# VIP1_VPDMA register map
Vendor: Texas Instruments
Registers are 32-bit, access per field, reset 0x0 unless marked. A register's access mark holds for its fields unless they carry their own. Offsets are as the file gives them; [hi:lo] are bit positions; {n}, {i} and the like mark numbered series; 'fields as' and 'values as' point back to an identical list.

## VIP1_VPDMA (part 5 of 5)
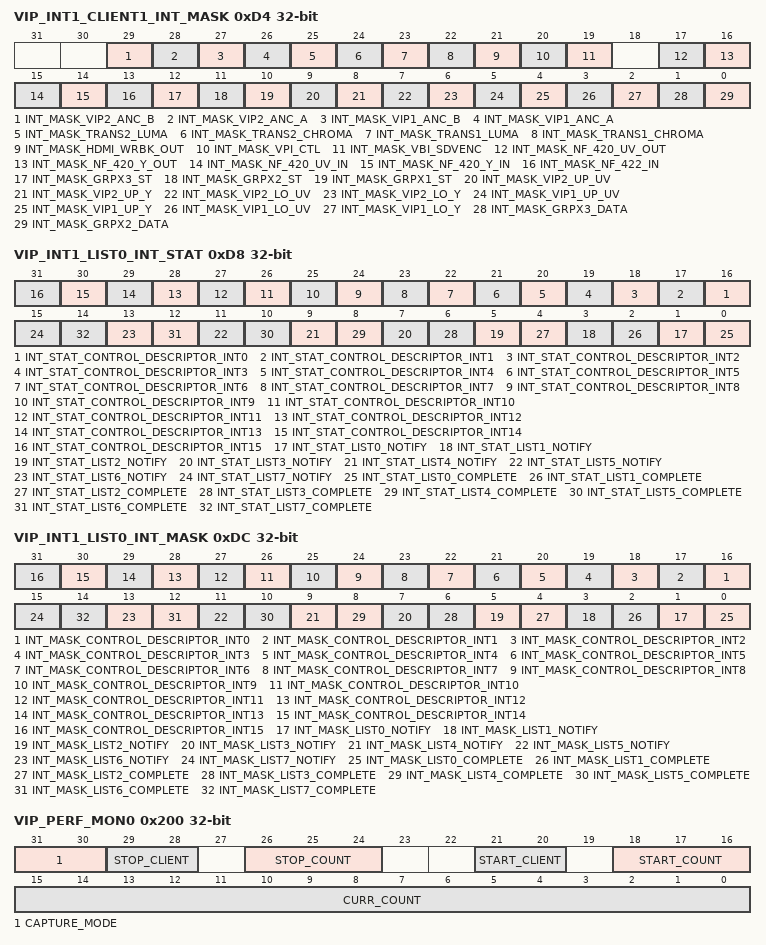
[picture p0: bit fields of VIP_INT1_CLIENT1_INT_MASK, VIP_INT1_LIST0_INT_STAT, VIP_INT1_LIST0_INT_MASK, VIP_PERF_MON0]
0xD4 VIP_INT1_CLIENT1_INT_MASK — The register gives the information of the interrupts that should be masked and not generate an interrupt for vpdma_int1.
  [29] INT_MASK_VIP2_ANC_B rw — The interrupt for should generate an interrupt on interrupt vpdma_int1. Write a 1 for the interrupt event to trigger the interrupt signal.
  [28] INT_MASK_VIP2_ANC_A rw — The interrupt for should generate an interrupt on interrupt vpdma_int1. Write a 1 for the interrupt event to trigger the interrupt signal.
  [27] INT_MASK_VIP1_ANC_B rw — The interrupt for should generate an interrupt on interrupt vpdma_int1. Write a 1 for the interrupt event to trigger the interrupt signal.
  [26] INT_MASK_VIP1_ANC_A rw — The interrupt for should generate an interrupt on interrupt vpdma_int1. Write a 1 for the interrupt event to trigger the interrupt signal.
  [25] INT_MASK_TRANS2_LUMA rw — The interrupt for should generate an interrupt on interrupt vpdma_int1. Write a 1 for the interrupt event to trigger the interrupt signal.
  [24] INT_MASK_TRANS2_CHROMA rw — The interrupt for should generate an interrupt on interrupt vpdma_int1. Write a 1 for the interrupt event to trigger the interrupt signal.
  [23] INT_MASK_TRANS1_LUMA rw — The interrupt for should generate an interrupt on interrupt vpdma_int1. Write a 1 for the interrupt event to trigger the interrupt signal.
  [22] INT_MASK_TRANS1_CHROMA rw — The interrupt for should generate an interrupt on interrupt vpdma_int1. Write a 1 for the interrupt event to trigger the interrupt signal.
  [21] INT_MASK_HDMI_WRBK_OUT rw — The interrupt for should generate an interrupt on interrupt vpdma_int1. Write a 1 for the interrupt event to trigger the interrupt signal.
  [20] INT_MASK_VPI_CTL rw — The interrupt for should generate an interrupt on interrupt vpdma_int1. Write a 1 for the interrupt event to trigger the interrupt signal.
  [19] INT_MASK_VBI_SDVENC rw — The interrupt for should generate an interrupt on interrupt vpdma_int1. Write a 1 for the interrupt event to trigger the interrupt signal.
  [17] INT_MASK_NF_420_UV_OUT rw — The interrupt for should generate an interrupt on interrupt vpdma_int1. Write a 1 for the interrupt event to trigger the interrupt signal.
  [16] INT_MASK_NF_420_Y_OUT rw — The interrupt for should generate an interrupt on interrupt vpdma_int1. Write a 1 for the interrupt event to trigger the interrupt signal.
  [15] INT_MASK_NF_420_UV_IN rw — The interrupt for should generate an interrupt on interrupt vpdma_int1. Write a 1 for the interrupt event to trigger the interrupt signal.
  [14] INT_MASK_NF_420_Y_IN rw — The interrupt for should generate an interrupt on interrupt vpdma_int1. Write a 1 for the interrupt event to trigger the interrupt signal.
  [13] INT_MASK_NF_422_IN rw — The interrupt for should generate an interrupt on interrupt vpdma_int1. Write a 1 for the interrupt event to trigger the interrupt signal.
  [12] INT_MASK_GRPX3_ST rw — The interrupt for should generate an interrupt on interrupt vpdma_int1. Write a 1 for the interrupt event to trigger the interrupt signal.
  [11] INT_MASK_GRPX2_ST rw — The interrupt for should generate an interrupt on interrupt vpdma_int1. Write a 1 for the interrupt event to trigger the interrupt signal.
  [10] INT_MASK_GRPX1_ST rw — The interrupt for should generate an interrupt on interrupt vpdma_int1. Write a 1 for the interrupt event to trigger the interrupt signal.
  [9] INT_MASK_VIP2_UP_UV rw — The interrupt for should generate an interrupt on interrupt vpdma_int1. Write a 1 for the interrupt event to trigger the interrupt signal.
  [8] INT_MASK_VIP2_UP_Y rw — The interrupt for should generate an interrupt on interrupt vpdma_int1. Write a 1 for the interrupt event to trigger the interrupt signal.
  [7] INT_MASK_VIP2_LO_UV rw — The interrupt for should generate an interrupt on interrupt vpdma_int1. Write a 1 for the interrupt event to trigger the interrupt signal.
  [6] INT_MASK_VIP2_LO_Y rw — The interrupt for should generate an interrupt on interrupt vpdma_int1. Write a 1 for the interrupt event to trigger the interrupt signal.
  [5] INT_MASK_VIP1_UP_UV rw — The interrupt for should generate an interrupt on interrupt vpdma_int1. Write a 1 for the interrupt event to trigger the interrupt signal.
  [4] INT_MASK_VIP1_UP_Y rw — The interrupt for should generate an interrupt on interrupt vpdma_int1. Write a 1 for the interrupt event to trigger the interrupt signal.
  [3] INT_MASK_VIP1_LO_UV rw — The interrupt for should generate an interrupt on interrupt vpdma_int1. Write a 1 for the interrupt event to trigger the interrupt signal.
  [2] INT_MASK_VIP1_LO_Y rw — The interrupt for should generate an interrupt on interrupt vpdma_int1. Write a 1 for the interrupt event to trigger the interrupt signal.
  [1] INT_MASK_GRPX3_DATA rw — The interrupt for should generate an interrupt on interrupt vpdma_int1. Write a 1 for the interrupt event to trigger the interrupt signal.
  [0] INT_MASK_GRPX2_DATA rw — The interrupt for should generate an interrupt on interrupt vpdma_int1. Write a 1 for the interrupt event to trigger the interrupt signal.
0xD8 VIP_INT1_LIST0_INT_STAT rw — This register gives the information of the interrupts that have triggered since last cleared by the process that is servicing vpdma_int1.
  [n+16] INT_STAT_CONTROL_DESCRIPTOR_INT{n} (n=0..15) — A Send Interrupt Control Descriptor has been received by the list manager with a source value of {n}. This event will cause a one to be set in this register until cleared by software. Write a 1 to this field to clear the value.
  [2n+1] INT_STAT_LIST{n}_NOTIFY (n=0..7) — A channel set by List {n} has completed and the Notify bit had been set in the descriptor for that channel. This event will cause a one to be set in this register until cleared by software. Write a 1 to this field to clear the value.
  [2n] INT_STAT_LIST{n}_COMPLETE (n=0..7) — List {n} has completed and a new list can be loaded. This event will cause a one to be set in this register until cleared by software. Write a 1 to this field to clear the value.
0xDC VIP_INT1_LIST0_INT_MASK rw — The register gives the information of the interrupts that should be masked and not generate an interrupt for vpdma_int1.
  [n+16] INT_MASK_CONTROL_DESCRIPTOR_INT{n} (n=0..15) — The interrupt for should generate an interrupt on interrupt vpdma_int1. Write a 1 for the interrupt event to trigger the interrupt signal.
  [2n+1] INT_MASK_LIST{n}_NOTIFY (n=0..7) — The interrupt for should generate an interrupt on interrupt vpdma_int1. Write a 1 for the interrupt event to trigger the interrupt signal.
  [2n] INT_MASK_LIST{n}_COMPLETE (n=0..7) — The interrupt for should generate an interrupt on interrupt vpdma_int1. Write a 1 for the interrupt event to trigger the interrupt signal.
0x200 VIP_PERF_MON0 — The register can be used to capture timing differences between events in the VPDMA\
  [31:30] CAPTURE_MODE rw — Sets how the counter should be updated. Updating this value will also clear the current counter stored value. 0: Running Average 1: Minimum Value 2: Maximum Value 3: Last Value
  [29:28] STOP_CLIENT rw — Sets the client whose event stops the performance monitor counter. 0: 1: vip2_anc_b 2: 3:
  [26:24] STOP_COUNT rw — Sets the value that stops the performance monitor counter. 0: command request 1: command accept 2: data request 3: data rcvd 4: data empty 5: data full 6: frame start 7: frame end
  [21:20] START_CLIENT rw — Sets the client whose event starts the performance monitor counter. 0: 1: vip2_anc_b 2: 3:
  [18:16] START_COUNT rw — Sets the value that starts the performance monitor counter. 0: command request 1: command accept 2: data request 3: data rcvd 4: data empty 5: data full 6: frame start 7: frame end
  [15:0] CURR_COUNT ro — The current value of the perfomance monitor counter
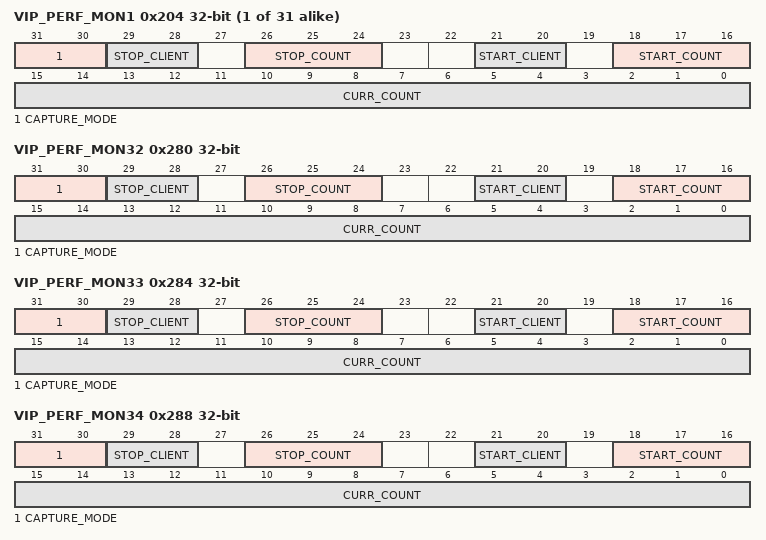
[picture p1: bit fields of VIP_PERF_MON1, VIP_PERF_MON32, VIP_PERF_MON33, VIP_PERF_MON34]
{0x200+4i} VIP_PERF_MON{i} (i=1..31) — The register can be used to capture timing differences between events in the VPDMA\
  [31:30] CAPTURE_MODE rw — Sets how the counter should be updated. Updating this value will also clear the current counter stored value. 0: Running Average 1: Minimum Value 2: Maximum Value 3: Last Value
  [29:28] STOP_CLIENT rw — Sets the client whose event stops the performance monitor counter. 0: 1: 2: 3:
  [26:24] STOP_COUNT rw — Sets the value that stops the performance monitor counter. 0: command request 1: command accept 2: data request 3: data rcvd 4: data empty 5: data full 6: frame start 7: frame end
  [21:20] START_CLIENT rw — Sets the client whose event starts the performance monitor counter. 0: 1: 2: 3:
  [18:16] START_COUNT rw — Sets the value that starts the performance monitor counter. 0: command request 1: command accept 2: data request 3: data rcvd 4: data empty 5: data full 6: frame start 7: frame end
  [15:0] CURR_COUNT ro — The current value of the perfomance monitor counter
0x280 VIP_PERF_MON32 — The register can be used to capture timing differences between events in the VPDMA\
  [31:30] CAPTURE_MODE rw — Sets how the counter should be updated. Updating this value will also clear the current counter stored value. 0: Running Average 1: Minimum Value 2: Maximum Value 3: Last Value
  [29:28] STOP_CLIENT rw — Sets the client whose event stops the performance monitor counter. 0: 1: 2: 3: vip1_lo_y
  [26:24] STOP_COUNT rw — Sets the value that stops the performance monitor counter. 0: command request 1: command accept 2: data request 3: data rcvd 4: data empty 5: data full 6: frame start 7: frame end
  [21:20] START_CLIENT rw — Sets the client whose event starts the performance monitor counter. 0: 1: 2: 3: vip1_lo_y
  [18:16] START_COUNT rw — Sets the value that starts the performance monitor counter. 0: command request 1: command accept 2: data request 3: data rcvd 4: data empty 5: data full 6: frame start 7: frame end
  [15:0] CURR_COUNT ro — The current value of the perfomance monitor counter
0x284 VIP_PERF_MON33 — The register can be used to capture timing differences between events in the VPDMA\
  [31:30] CAPTURE_MODE rw — Sets how the counter should be updated. Updating this value will also clear the current counter stored value. 0: Running Average 1: Minimum Value 2: Maximum Value 3: Last Value
  [29:28] STOP_CLIENT rw — Sets the client whose event stops the performance monitor counter. 0: 1: 2: vip1_lo_y 3: vip1_lo_uv
  [26:24] STOP_COUNT rw — Sets the value that stops the performance monitor counter. 0: command request 1: command accept 2: data request 3: data rcvd 4: data empty 5: data full 6: frame start 7: frame end
  [21:20] START_CLIENT rw — Sets the client whose event starts the performance monitor counter. 0: 1: 2: vip1_lo_y 3: vip1_lo_uv
  [18:16] START_COUNT rw — Sets the value that starts the performance monitor counter. 0: command request 1: command accept 2: data request 3: data rcvd 4: data empty 5: data full 6: frame start 7: frame end
  [15:0] CURR_COUNT ro — The current value of the perfomance monitor counter
0x288 VIP_PERF_MON34 — The register can be used to capture timing differences between events in the VPDMA\
  [31:30] CAPTURE_MODE rw — Sets how the counter should be updated. Updating this value will also clear the current counter stored value. 0: Running Average 1: Minimum Value 2: Maximum Value 3: Last Value
  [29:28] STOP_CLIENT rw — Sets the client whose event stops the performance monitor counter. 0: vip1_lo_y 1: 2: vip1_lo_uv 3: vip1_up_y
  [26:24] STOP_COUNT rw — Sets the value that stops the performance monitor counter. 0: command request 1: command accept 2: data request 3: data rcvd 4: data empty 5: data full 6: frame start 7: frame end
  [21:20] START_CLIENT rw — Sets the client whose event starts the performance monitor counter. 0: vip1_lo_y 1: 2: vip1_lo_uv 3: vip1_up_y
  [18:16] START_COUNT rw — Sets the value that starts the performance monitor counter. 0: command request 1: command accept 2: data request 3: data rcvd 4: data empty 5: data full 6: frame start 7: frame end
  [15:0] CURR_COUNT ro — The current value of the perfomance monitor counter
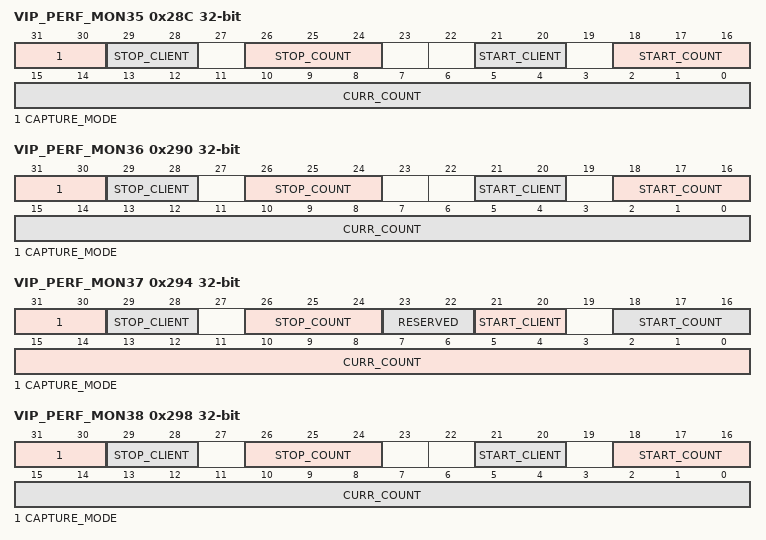
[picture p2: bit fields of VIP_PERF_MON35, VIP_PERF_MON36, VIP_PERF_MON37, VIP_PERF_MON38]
0x28C VIP_PERF_MON35 — The register can be used to capture timing differences between events in the VPDMA\
  [31:30] CAPTURE_MODE rw — Sets how the counter should be updated. Updating this value will also clear the current counter stored value. 0: Running Average 1: Minimum Value 2: Maximum Value 3: Last Value
  [29:28] STOP_CLIENT rw — Sets the client whose event stops the performance monitor counter. 0: vip1_lo_uv 1: vip1_lo_y 2: vip1_up_y 3: vip1_up_uv
  [26:24] STOP_COUNT rw — Sets the value that stops the performance monitor counter. 0: command request 1: command accept 2: data request 3: data rcvd 4: data empty 5: data full 6: frame start 7: frame end
  [21:20] START_CLIENT rw — Sets the client whose event starts the performance monitor counter. 0: vip1_lo_uv 1: vip1_lo_y 2: vip1_up_y 3: vip1_up_uv
  [18:16] START_COUNT rw — Sets the value that starts the performance monitor counter. 0: command request 1: command accept 2: data request 3: data rcvd 4: data empty 5: data full 6: frame start 7: frame end
  [15:0] CURR_COUNT ro — The current value of the perfomance monitor counter
0x290 VIP_PERF_MON36 — The register can be used to capture timing differences between events in the VPDMA\
  [31:30] CAPTURE_MODE rw — Sets how the counter should be updated. Updating this value will also clear the current counter stored value. 0: Running Average 1: Minimum Value 2: Maximum Value 3: Last Value
  [29:28] STOP_CLIENT rw — Sets the client whose event stops the performance monitor counter. 0: vip1_up_y 1: vip1_lo_uv 2: vip1_up_uv 3: vip2_lo_y
  [26:24] STOP_COUNT rw — Sets the value that stops the performance monitor counter. 0: command request 1: command accept 2: data request 3: data rcvd 4: data empty 5: data full 6: frame start 7: frame end
  [21:20] START_CLIENT rw — Sets the client whose event starts the performance monitor counter. 0: vip1_up_y 1: vip1_lo_uv 2: vip1_up_uv 3: vip2_lo_y
  [18:16] START_COUNT rw — Sets the value that starts the performance monitor counter. 0: command request 1: command accept 2: data request 3: data rcvd 4: data empty 5: data full 6: frame start 7: frame end
  [15:0] CURR_COUNT ro — The current value of the perfomance monitor counter
0x294 VIP_PERF_MON37 — The register can be used to capture timing differences between events in the VPDMA\
  [31:30] CAPTURE_MODE rw — Sets how the counter should be updated. Updating this value will also clear the current counter stored value. 0: Running Average 1: Minimum Value 2: Maximum Value 3: Last Value
  [29:28] STOP_CLIENT rw — Sets the client whose event stops the performance monitor counter. 0: vip1_up_uv 1: vip1_up_y 2: vip2_lo_y 3: vip2_lo_uv
  [26:24] STOP_COUNT rw
  [23:22] RESERVED ro — Sets the value that stops the performance monitor counter. 0: command request 1: command accept 2: data request 3: data rcvd 4: data empty 5: data full 6: frame start 7: frame end
  [21:20] START_CLIENT rw — Sets the client whose event starts the performance monitor counter. 0: vip1_up_uv 1: vip1_up_y 2: vip2_lo_y 3: vip2_lo_uv
  [18:16] START_COUNT rw — Sets the value that starts the performance monitor counter. 0: command request 1: command accept 2: data request 3: data rcvd 4: data empty 5: data full 6: frame start 7: frame end
  [15:0] CURR_COUNT ro — The current value of the perfomance monitor counter
0x298 VIP_PERF_MON38 — The register can be used to capture timing differences between events in the VPDMA\
  [31:30] CAPTURE_MODE rw — Sets how the counter should be updated. Updating this value will also clear the current counter stored value. 0: Running Average 1: Minimum Value 2: Maximum Value 3: Last Value
  [29:28] STOP_CLIENT rw — Sets the client whose event stops the performance monitor counter. 0: vip2_lo_y 1: vip1_up_uv 2: vip2_lo_uv 3: vip2_up_y
  [26:24] STOP_COUNT rw — Sets the value that stops the performance monitor counter. 0: command request 1: command accept 2: data request 3: data rcvd 4: data empty 5: data full 6: frame start 7: frame end
  [21:20] START_CLIENT rw — Sets the client whose event starts the performance monitor counter. 0: vip2_lo_y 1: vip1_up_uv 2: vip2_lo_uv 3: vip2_up_y
  [18:16] START_COUNT rw — Sets the value that starts the performance monitor counter. 0: command request 1: command accept 2: data request 3: data rcvd 4: data empty 5: data full 6: frame start 7: frame end
  [15:0] CURR_COUNT ro — The current value of the perfomance monitor counter
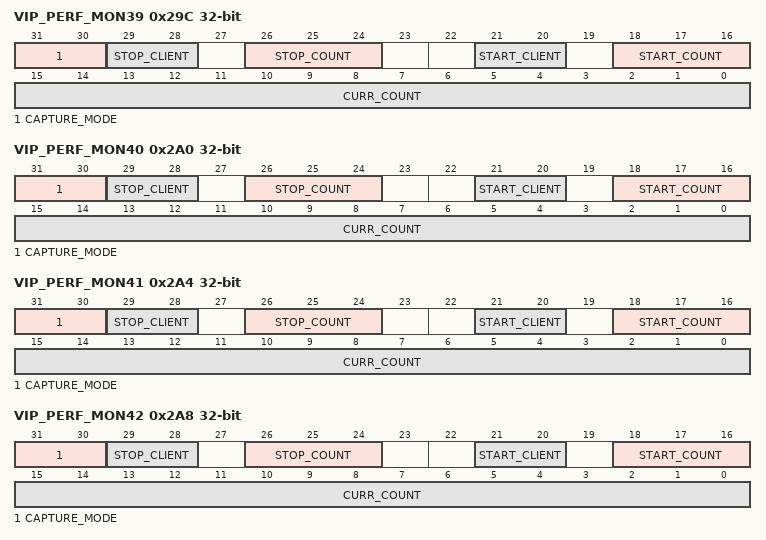
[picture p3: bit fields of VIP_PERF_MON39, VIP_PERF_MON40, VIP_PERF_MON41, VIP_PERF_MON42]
0x29C VIP_PERF_MON39 — The register can be used to capture timing differences between events in the VPDMA\
  [31:30] CAPTURE_MODE rw — Sets how the counter should be updated. Updating this value will also clear the current counter stored value. 0: Running Average 1: Minimum Value 2: Maximum Value 3: Last Value
  [29:28] STOP_CLIENT rw — Sets the client whose event stops the performance monitor counter. 0: vip2_lo_uv 1: vip2_lo_y 2: vip2_up_y 3: vip2_up_uv
  [26:24] STOP_COUNT rw — Sets the value that stops the performance monitor counter. 0: command request 1: command accept 2: data request 3: data rcvd 4: data empty 5: data full 6: frame start 7: frame end
  [21:20] START_CLIENT rw — Sets the client whose event starts the performance monitor counter. 0: vip2_lo_uv 1: vip2_lo_y 2: vip2_up_y 3: vip2_up_uv
  [18:16] START_COUNT rw — Sets the value that starts the performance monitor counter. 0: command request 1: command accept 2: data request 3: data rcvd 4: data empty 5: data full 6: frame start 7: frame end
  [15:0] CURR_COUNT ro — The current value of the perfomance monitor counter
0x2A0 VIP_PERF_MON40 — The register can be used to capture timing differences between events in the VPDMA\
  [31:30] CAPTURE_MODE rw — Sets how the counter should be updated. Updating this value will also clear the current counter stored value. 0: Running Average 1: Minimum Value 2: Maximum Value 3: Last Value
  [29:28] STOP_CLIENT rw — Sets the client whose event stops the performance monitor counter. 0: vip2_up_y 1: vip2_lo_uv 2: vip2_up_uv 3:
  [26:24] STOP_COUNT rw — Sets the value that stops the performance monitor counter. 0: command request 1: command accept 2: data request 3: data rcvd 4: data empty 5: data full 6: frame start 7: frame end
  [21:20] START_CLIENT rw — Sets the client whose event starts the performance monitor counter. 0: vip2_up_y 1: vip2_lo_uv 2: vip2_up_uv 3:
  [18:16] START_COUNT rw — Sets the value that starts the performance monitor counter. 0: command request 1: command accept 2: data request 3: data rcvd 4: data empty 5: data full 6: frame start 7: frame end
  [15:0] CURR_COUNT ro — The current value of the perfomance monitor counter
0x2A4 VIP_PERF_MON41 — The register can be used to capture timing differences between events in the VPDMA\
  [31:30] CAPTURE_MODE rw — Sets how the counter should be updated. Updating this value will also clear the current counter stored value. 0: Running Average 1: Minimum Value 2: Maximum Value 3: Last Value
  [29:28] STOP_CLIENT rw — Sets the client whose event stops the performance monitor counter. 0: vip2_up_uv 1: vip2_up_y 2: 3:
  [26:24] STOP_COUNT rw — Sets the value that stops the performance monitor counter. 0: command request 1: command accept 2: data request 3: data rcvd 4: data empty 5: data full 6: frame start 7: frame end
  [21:20] START_CLIENT rw — Sets the client whose event starts the performance monitor counter. 0: vip2_up_uv 1: vip2_up_y 2: 3:
  [18:16] START_COUNT rw — Sets the value that starts the performance monitor counter. 0: command request 1: command accept 2: data request 3: data rcvd 4: data empty 5: data full 6: frame start 7: frame end
  [15:0] CURR_COUNT ro — The current value of the perfomance monitor counter
0x2A8 VIP_PERF_MON42 — The register can be used to capture timing differences between events in the VPDMA\
  [31:30] CAPTURE_MODE rw — Sets how the counter should be updated. Updating this value will also clear the current counter stored value. 0: Running Average 1: Minimum Value 2: Maximum Value 3: Last Value
  [29:28] STOP_CLIENT rw — Sets the client whose event stops the performance monitor counter. 0: 1: vip2_up_uv 2: 3:
  [26:24] STOP_COUNT rw — Sets the value that stops the performance monitor counter. 0: command request 1: command accept 2: data request 3: data rcvd 4: data empty 5: data full 6: frame start 7: frame end
  [21:20] START_CLIENT rw — Sets the client whose event starts the performance monitor counter. 0: 1: vip2_up_uv 2: 3:
  [18:16] START_COUNT rw — Sets the value that starts the performance monitor counter. 0: command request 1: command accept 2: data request 3: data rcvd 4: data empty 5: data full 6: frame start 7: frame end
  [15:0] CURR_COUNT ro — The current value of the perfomance monitor counter
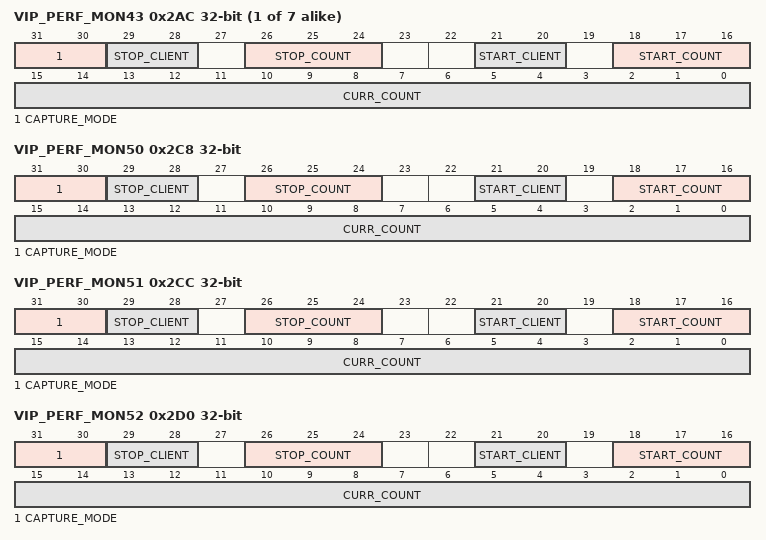
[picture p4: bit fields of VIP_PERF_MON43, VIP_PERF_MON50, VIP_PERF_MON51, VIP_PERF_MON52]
{0x200+4i} VIP_PERF_MON{i} (i=43..49) — The register can be used to capture timing differences between events in the VPDMA\
  fields as VIP_PERF_MON1
0x2C8 VIP_PERF_MON50 — The register can be used to capture timing differences between events in the VPDMA\
  [31:30] CAPTURE_MODE rw — Sets how the counter should be updated. Updating this value will also clear the current counter stored value. 0: Running Average 1: Minimum Value 2: Maximum Value 3: Last Value
  [29:28] STOP_CLIENT rw — Sets the client whose event stops the performance monitor counter. 0: 1: 2: 3: vpi_ctl
  [26:24] STOP_COUNT rw — Sets the value that stops the performance monitor counter. 0: command request 1: command accept 2: data request 3: data rcvd 4: data empty 5: data full 6: frame start 7: frame end
  [21:20] START_CLIENT rw — Sets the client whose event starts the performance monitor counter. 0: 1: 2: 3: vpi_ctl
  [18:16] START_COUNT rw — Sets the value that starts the performance monitor counter. 0: command request 1: command accept 2: data request 3: data rcvd 4: data empty 5: data full 6: frame start 7: frame end
  [15:0] CURR_COUNT ro — The current value of the perfomance monitor counter
0x2CC VIP_PERF_MON51 — The register can be used to capture timing differences between events in the VPDMA\
  [31:30] CAPTURE_MODE rw — Sets how the counter should be updated. Updating this value will also clear the current counter stored value. 0: Running Average 1: Minimum Value 2: Maximum Value 3: Last Value
  [29:28] STOP_CLIENT rw — Sets the client whose event stops the performance monitor counter. 0: 1: 2: vpi_ctl 3:
  [26:24] STOP_COUNT rw — Sets the value that stops the performance monitor counter. 0: command request 1: command accept 2: data request 3: data rcvd 4: data empty 5: data full 6: frame start 7: frame end
  [21:20] START_CLIENT rw — Sets the client whose event starts the performance monitor counter. 0: 1: 2: vpi_ctl 3:
  [18:16] START_COUNT rw — Sets the value that starts the performance monitor counter. 0: command request 1: command accept 2: data request 3: data rcvd 4: data empty 5: data full 6: frame start 7: frame end
  [15:0] CURR_COUNT ro — The current value of the perfomance monitor counter
0x2D0 VIP_PERF_MON52 — The register can be used to capture timing differences between events in the VPDMA\
  [31:30] CAPTURE_MODE rw — Sets how the counter should be updated. Updating this value will also clear the current counter stored value. 0: Running Average 1: Minimum Value 2: Maximum Value 3: Last Value
  [29:28] STOP_CLIENT rw — Sets the client whose event stops the performance monitor counter. 0: vpi_ctl 1: 2: 3:
  [26:24] STOP_COUNT rw — Sets the value that stops the performance monitor counter. 0: command request 1: command accept 2: data request 3: data rcvd 4: data empty 5: data full 6: frame start 7: frame end
  [21:20] START_CLIENT rw — Sets the client whose event starts the performance monitor counter. 0: vpi_ctl 1: 2: 3:
  [18:16] START_COUNT rw — Sets the value that starts the performance monitor counter. 0: command request 1: command accept 2: data request 3: data rcvd 4: data empty 5: data full 6: frame start 7: frame end
  [15:0] CURR_COUNT ro — The current value of the perfomance monitor counter
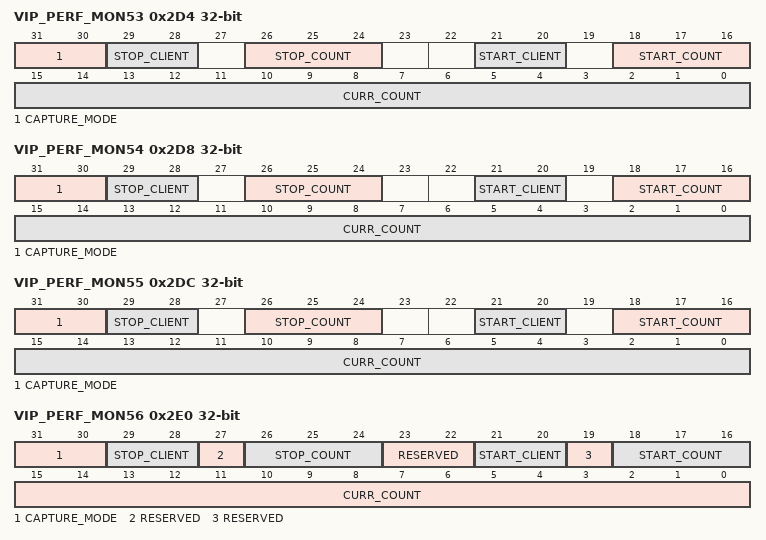
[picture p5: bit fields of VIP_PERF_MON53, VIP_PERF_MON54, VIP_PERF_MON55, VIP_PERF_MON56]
0x2D4 VIP_PERF_MON53 — The register can be used to capture timing differences between events in the VPDMA\
  [31:30] CAPTURE_MODE rw — Sets how the counter should be updated. Updating this value will also clear the current counter stored value. 0: Running Average 1: Minimum Value 2: Maximum Value 3: Last Value
  [29:28] STOP_CLIENT rw — Sets the client whose event stops the performance monitor counter. 0: 1: vpi_ctl 2: 3:
  [26:24] STOP_COUNT rw — Sets the value that stops the performance monitor counter. 0: command request 1: command accept 2: data request 3: data rcvd 4: data empty 5: data full 6: frame start 7: frame end
  [21:20] START_CLIENT rw — Sets the client whose event starts the performance monitor counter. 0: 1: vpi_ctl 2: 3:
  [18:16] START_COUNT rw — Sets the value that starts the performance monitor counter. 0: command request 1: command accept 2: data request 3: data rcvd 4: data empty 5: data full 6: frame start 7: frame end
  [15:0] CURR_COUNT ro — The current value of the perfomance monitor counter
0x2D8 VIP_PERF_MON54 — The register can be used to capture timing differences between events in the VPDMA\
  fields as VIP_PERF_MON1
0x2DC VIP_PERF_MON55 — The register can be used to capture timing differences between events in the VPDMA\
  fields as VIP_PERF_MON1
0x2E0 VIP_PERF_MON56 — The register can be used to capture timing differences between events in the VPDMA\
  [31:30] CAPTURE_MODE rw — Sets how the counter should be updated. Updating this value will also clear the current counter stored value. 0: Running Average 1: Minimum Value 2: Maximum Value 3: Last Value
  [29:28] STOP_CLIENT rw
  [27] RESERVED ro — Sets the client whose event stops the performance monitor counter. 0: 1: 2: 3: vip1_anc_a
  [26:24] STOP_COUNT rw
  [23:22] RESERVED ro — Sets the value that stops the performance monitor counter. 0: command request 1: command accept 2: data request 3: data rcvd 4: data empty 5: data full 6: frame start 7: frame end
  [21:20] START_CLIENT rw
  [19] RESERVED ro — Sets the client whose event starts the performance monitor counter. 0: 1: 2: 3: vip1_anc_a
  [18:16] START_COUNT rw — Sets the value that starts the performance monitor counter. 0: command request 1: command accept 2: data request 3: data rcvd 4: data empty 5: data full 6: frame start 7: frame end
  [15:0] CURR_COUNT ro — The current value of the perfomance monitor counter
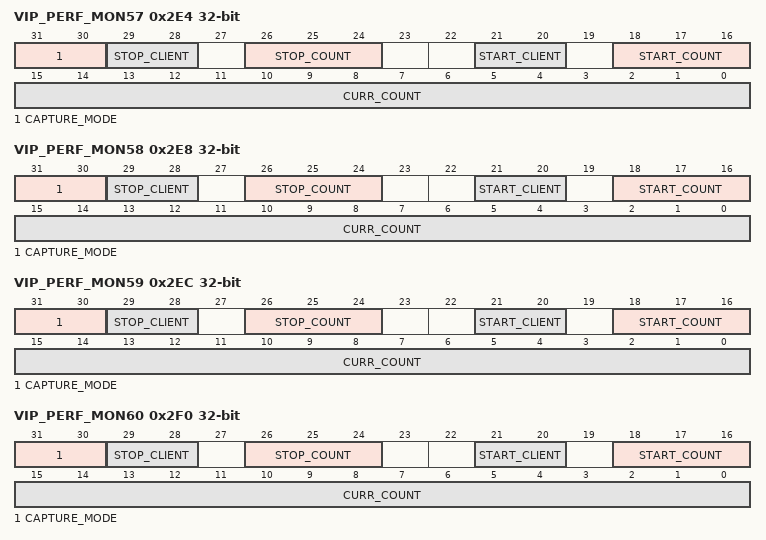
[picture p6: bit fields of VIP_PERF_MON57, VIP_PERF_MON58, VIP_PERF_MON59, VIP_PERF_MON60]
0x2E4 VIP_PERF_MON57 — The register can be used to capture timing differences between events in the VPDMA\
  [31:30] CAPTURE_MODE rw — Sets how the counter should be updated. Updating this value will also clear the current counter stored value. 0: Running Average 1: Minimum Value 2: Maximum Value 3: Last Value
  [29:28] STOP_CLIENT rw — Sets the client whose event stops the performance monitor counter. 0: 1: 2: vip1_anc_a 3: vip1_anc_b
  [26:24] STOP_COUNT rw — Sets the value that stops the performance monitor counter. 0: command request 1: command accept 2: data request 3: data rcvd 4: data empty 5: data full 6: frame start 7: frame end
  [21:20] START_CLIENT rw — Sets the client whose event starts the performance monitor counter. 0: 1: 2: vip1_anc_a 3: vip1_anc_b
  [18:16] START_COUNT rw — Sets the value that starts the performance monitor counter. 0: command request 1: command accept 2: data request 3: data rcvd 4: data empty 5: data full 6: frame start 7: frame end
  [15:0] CURR_COUNT ro — The current value of the perfomance monitor counter
0x2E8 VIP_PERF_MON58 — The register can be used to capture timing differences between events in the VPDMA\
  [31:30] CAPTURE_MODE rw — Sets how the counter should be updated. Updating this value will also clear the current counter stored value. 0: Running Average 1: Minimum Value 2: Maximum Value 3: Last Value
  [29:28] STOP_CLIENT rw — Sets the client whose event stops the performance monitor counter. 0: vip1_anc_a 1: 2: vip1_anc_b 3: vip2_anc_a
  [26:24] STOP_COUNT rw — Sets the value that stops the performance monitor counter. 0: command request 1: command accept 2: data request 3: data rcvd 4: data empty 5: data full 6: frame start 7: frame end
  [21:20] START_CLIENT rw — Sets the client whose event starts the performance monitor counter. 0: vip1_anc_a 1: 2: vip1_anc_b 3: vip2_anc_a
  [18:16] START_COUNT rw — Sets the value that starts the performance monitor counter. 0: command request 1: command accept 2: data request 3: data rcvd 4: data empty 5: data full 6: frame start 7: frame end
  [15:0] CURR_COUNT ro — The current value of the perfomance monitor counter
0x2EC VIP_PERF_MON59 — The register can be used to capture timing differences between events in the VPDMA\
  [31:30] CAPTURE_MODE rw — Sets how the counter should be updated. Updating this value will also clear the current counter stored value. 0: Running Average 1: Minimum Value 2: Maximum Value 3: Last Value
  [29:28] STOP_CLIENT rw — Sets the client whose event stops the performance monitor counter. 0: vip1_anc_b 1: vip1_anc_a 2: vip2_anc_a 3: vip2_anc_b
  [26:24] STOP_COUNT rw — Sets the value that stops the performance monitor counter. 0: command request 1: command accept 2: data request 3: data rcvd 4: data empty 5: data full 6: frame start 7: frame end
  [21:20] START_CLIENT rw — Sets the client whose event starts the performance monitor counter. 0: vip1_anc_b 1: vip1_anc_a 2: vip2_anc_a 3: vip2_anc_b
  [18:16] START_COUNT rw — Sets the value that starts the performance monitor counter. 0: command request 1: command accept 2: data request 3: data rcvd 4: data empty 5: data full 6: frame start 7: frame end
  [15:0] CURR_COUNT ro — The current value of the perfomance monitor counter
0x2F0 VIP_PERF_MON60 — The register can be used to capture timing differences between events in the VPDMA\
  [31:30] CAPTURE_MODE rw — Sets how the counter should be updated. Updating this value will also clear the current counter stored value. 0: Running Average 1: Minimum Value 2: Maximum Value 3: Last Value
  [29:28] STOP_CLIENT rw — Sets the client whose event stops the performance monitor counter. 0: vip2_anc_a 1: vip1_anc_b 2: vip2_anc_b 3:
  [26:24] STOP_COUNT rw — Sets the value that stops the performance monitor counter. 0: command request 1: command accept 2: data request 3: data rcvd 4: data empty 5: data full 6: frame start 7: frame end
  [21:20] START_CLIENT rw — Sets the client whose event starts the performance monitor counter. 0: vip2_anc_a 1: vip1_anc_b 2: vip2_anc_b 3:
  [18:16] START_COUNT rw — Sets the value that starts the performance monitor counter. 0: command request 1: command accept 2: data request 3: data rcvd 4: data empty 5: data full 6: frame start 7: frame end
  [15:0] CURR_COUNT ro — The current value of the perfomance monitor counter
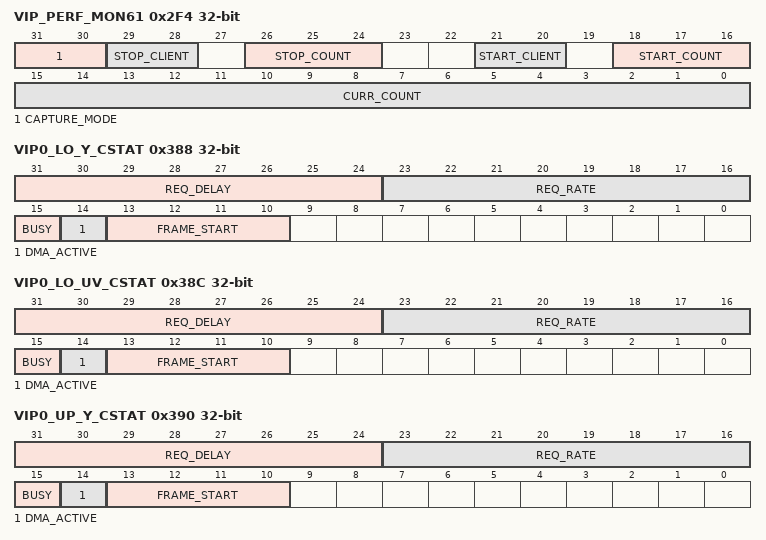
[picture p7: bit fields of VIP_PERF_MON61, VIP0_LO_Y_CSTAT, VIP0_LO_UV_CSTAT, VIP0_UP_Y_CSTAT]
0x2F4 VIP_PERF_MON61 — The register can be used to capture timing differences between events in the VPDMA\
  [31:30] CAPTURE_MODE rw — Sets how the counter should be updated. Updating this value will also clear the current counter stored value. 0: Running Average 1: Minimum Value 2: Maximum Value 3: Last Value
  [29:28] STOP_CLIENT rw — Sets the client whose event stops the performance monitor counter. 0: vip2_anc_b 1: vip2_anc_a 2: 3:
  [26:24] STOP_COUNT rw — Sets the value that stops the performance monitor counter. 0: command request 1: command accept 2: data request 3: data rcvd 4: data empty 5: data full 6: frame start 7: frame end
  [21:20] START_CLIENT rw — Sets the client whose event starts the performance monitor counter. 0: vip2_anc_b 1: vip2_anc_a 2: 3:
  [18:16] START_COUNT rw — Sets the value that starts the performance monitor counter. 0: command request 1: command accept 2: data request 3: data rcvd 4: data empty 5: data full 6: frame start 7: frame end
  [15:0] CURR_COUNT ro — The current value of the perfomance monitor counter
0x388 VIP0_LO_Y_CSTAT — The register holds status information and control for the client.\
  [31:24] REQ_DELAY rw — The minimum number of clock cycles between requests being issued. This value is multiplied by 32 to get the actual number of cycles..This value is only accurate for the current frame. The internal counters used to calculate the rate are reset when a new frame begins and the first request of a frame will go as soon as possible.
  [23:16] REQ_RATE ro — The number of clock cycles between the last two requests issued. This value is multiplied by 32 to get the actual number of cycles.This value is only accurate for the current frame. The internal counters used to calculate the rate are reset when a new frame begins.
  [15] BUSY ro — Signals if the client is currently active. This bit is set as soon as we the channel is received by the client from the list manager and is cleared when the channel is cleared from the shared memory.
  [14] DMA_ACTIVE ro — Signals if the client is currently actively sending DMA requests
  [13:10] FRAME_START rw — The source of the start frame event for the client.\ 0 : Change in value of hdmi_field_id\ 1 : Change in value of dvo2_field_id\ 2 : Change in value of hdcomp_field_id\ 3 : Change in value of sd_field_id\ 4 : Use List Manager Internal Field0\ 5 : Use List Manager Internal Field1\ 6 : Use List Manager Internal Field2\ 7 : Start on channel active
0x38C VIP0_LO_UV_CSTAT — The register holds status information and control for the client.\
  fields as VIP0_LO_Y_CSTAT
0x390 VIP0_UP_Y_CSTAT — The register holds status information and control for the client.\
  fields as VIP0_LO_Y_CSTAT
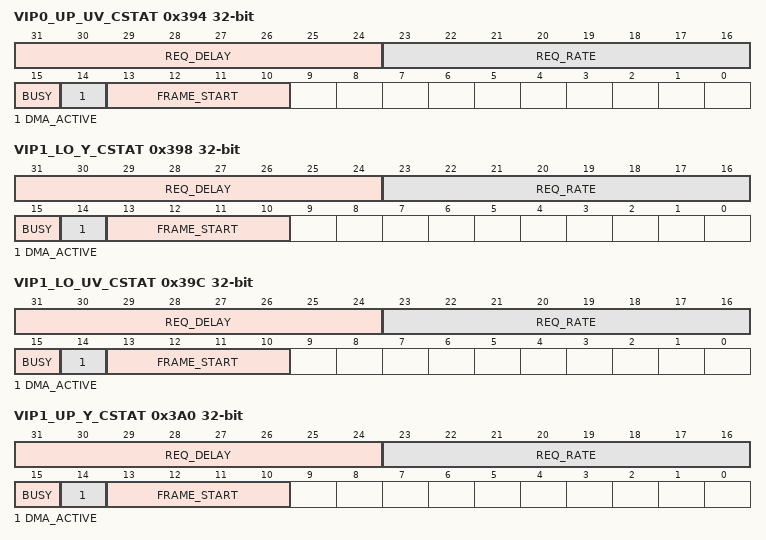
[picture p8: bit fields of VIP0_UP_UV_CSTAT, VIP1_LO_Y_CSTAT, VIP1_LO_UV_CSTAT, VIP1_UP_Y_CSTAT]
0x394 VIP0_UP_UV_CSTAT — The register holds status information and control for the client.\
  fields as VIP0_LO_Y_CSTAT
0x398 VIP1_LO_Y_CSTAT — The register holds status information and control for the client.\
  fields as VIP0_LO_Y_CSTAT
0x39C VIP1_LO_UV_CSTAT — The register holds status information and control for the client.\
  fields as VIP0_LO_Y_CSTAT
0x3A0 VIP1_UP_Y_CSTAT — The register holds status information and control for the client.\
  fields as VIP0_LO_Y_CSTAT
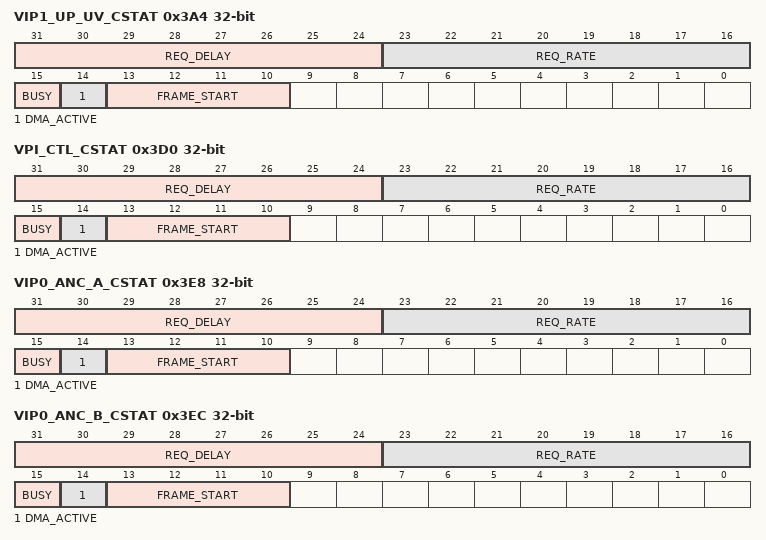
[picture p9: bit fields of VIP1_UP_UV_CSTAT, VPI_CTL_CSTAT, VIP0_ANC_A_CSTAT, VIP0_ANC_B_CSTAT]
0x3A4 VIP1_UP_UV_CSTAT — The register holds status information and control for the client.\
  fields as VIP0_LO_Y_CSTAT
0x3D0 VPI_CTL_CSTAT — The register holds status information and control for the client.\
  fields as VIP0_LO_Y_CSTAT
0x3E8 VIP0_ANC_A_CSTAT — The register holds status information and control for the client.\
  fields as VIP0_LO_Y_CSTAT
0x3EC VIP0_ANC_B_CSTAT — The register holds status information and control for the client.\
  fields as VIP0_LO_Y_CSTAT
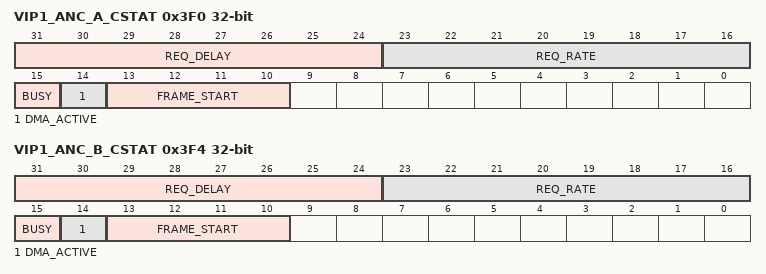
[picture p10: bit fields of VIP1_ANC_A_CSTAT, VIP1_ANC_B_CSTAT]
0x3F0 VIP1_ANC_A_CSTAT — The register holds status information and control for the client.\
  fields as VIP0_LO_Y_CSTAT
0x3F4 VIP1_ANC_B_CSTAT — The register holds status information and control for the client.\
  [31:24] REQ_DELAY rw — The minimum number of clock cycles between requests being issued. This value is multiplied by 32 to get the actual number of cycles.This value is only accurate for the current frame. The internal counters used to calculate the rate are reset when a new frame begins and the first request of a frame will go as soon as possible.
  [23:16] REQ_RATE ro — The number of clock cycles between the last two requests issued. This value is multiplied by 32 to get the actual number of cycles.This value is only accurate for the current frame. The internal counters used to calculate the rate are reset when a new frame begins.
  [15] BUSY ro — Signals if the client is currently active. This bit is set as soon as we the channel is received by the client from the list manager and is cleared when the channel is cleared from the shared memory.
  [14] DMA_ACTIVE ro — Signals if the client is currently actively sending DMA requests
  [13:10] FRAME_START rw — The source of the start frame event for the client.\ 0 : Change in value of hdmi_field_id\ 1 : Change in value of dvo2_field_id\ 2 : Change in value of hdcomp_field_id\ 3 : Change in value of sd_field_id\ 4 : Use List Manager Internal Field0\ 5 : Use List Manager Internal Field1\ 6 : Use List Manager Internal Field2\ 7 : Start on channel active
